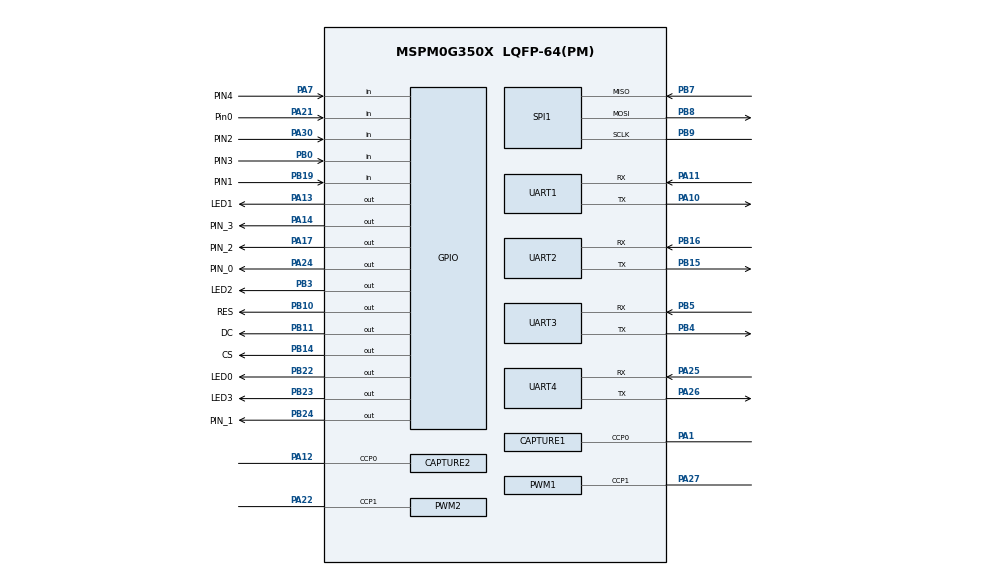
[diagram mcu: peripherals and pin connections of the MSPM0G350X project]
/**
 * @cliArgs --device "MSPM0G350X" --part "Default" --package "LQFP-64(PM)" --product "mspm0_sdk@2.10.00.04"
 * @versions {"tool":"1.26.2+4477"}
 */

/**
 * Import the modules used in this configuration.
 */
const ADC12         = scripting.addModule("/ti/driverlib/ADC12", {}, false);
const ADC121        = ADC12.addInstance();
const CAPTURE       = scripting.addModule("/ti/driverlib/CAPTURE", {}, false);
const CAPTURE1      = CAPTURE.addInstance();
const CAPTURE2      = CAPTURE.addInstance();
const GPIO          = scripting.addModule("/ti/driverlib/GPIO", {}, false);
const GPIO1         = GPIO.addInstance();
const GPIO2         = GPIO.addInstance();
const GPIO3         = GPIO.addInstance();
const GPIO4         = GPIO.addInstance();
const GPIO5         = GPIO.addInstance();
const GPIO6         = GPIO.addInstance();
const GPIO7         = GPIO.addInstance();
const GPIO8         = GPIO.addInstance();
const GPIO9         = GPIO.addInstance();
const MATHACL       = scripting.addModule("/ti/driverlib/MATHACL");
const PWM           = scripting.addModule("/ti/driverlib/PWM", {}, false);
const PWM1          = PWM.addInstance();
const PWM2          = PWM.addInstance();
const PWM3          = PWM.addInstance();
const SPI           = scripting.addModule("/ti/driverlib/SPI", {}, false);
const SPI1          = SPI.addInstance();
const SYSCTL        = scripting.addModule("/ti/driverlib/SYSCTL");
const SYSTICK       = scripting.addModule("/ti/driverlib/SYSTICK");
const TIMER         = scripting.addModule("/ti/driverlib/TIMER", {}, false);
const TIMER1        = TIMER.addInstance();
const UART          = scripting.addModule("/ti/driverlib/UART", {}, false);
const UART1         = UART.addInstance();
const UART2         = UART.addInstance();
const UART3         = UART.addInstance();
const UART4         = UART.addInstance();
const ProjectConfig = scripting.addModule("/ti/project_config/ProjectConfig");

/**
 * Write custom configuration values to the imported modules.
 */
const divider6       = system.clockTree["PLL_CLK2X_DIV"];
divider6.divideValue = 4;

const divider9       = system.clockTree["UDIV"];
divider9.divideValue = 2;

const multiplier2         = system.clockTree["PLL_QDIV"];
multiplier2.multiplyValue = 4;

const mux4       = system.clockTree["EXHFMUX"];
mux4.inputSelect = "EXHFMUX_XTAL";

const mux8       = system.clockTree["HSCLKMUX"];
mux8.inputSelect = "HSCLKMUX_SYSPLL0";

const mux12       = system.clockTree["SYSPLLMUX"];
mux12.inputSelect = "zSYSPLLMUX_HFCLK";

const pinFunction4        = system.clockTree["HFXT"];
pinFunction4.inputFreq    = 40;
pinFunction4.enable       = true;
pinFunction4.HFXTStartup  = 10;
pinFunction4.HFCLKMonitor = true;

ADC121.$name                      = "ADC12_0";
ADC121.peripheral.$assign         = "ADC1";
ADC121.peripheral.adcPin0.$assign = "PA15";
ADC121.adcPin0Config.$name        = "ti_driverlib_gpio_GPIOPinGeneric12";

const Board = scripting.addModule("/ti/driverlib/Board", {}, false);

CAPTURE1.captMode                           = "COMBINED";
CAPTURE1.interrupts                         = ["CC1_DN","ZERO"];
CAPTURE1.timerClkPrescale                   = 2;
CAPTURE1.timerPeriod                        = "3.2768ms";
CAPTURE1.$name                              = "CAPTURE_Up";
CAPTURE1.captFilter                         = true;
CAPTURE1.filterPeriod                       = "PER_8";
CAPTURE1.peripheral.$assign                 = "TIMG8";
CAPTURE1.peripheral.ccp0Pin.$assign         = "PA1";
CAPTURE1.ccp0PinConfig.hideOutputInversion  = scripting.forceWrite(false);
CAPTURE1.ccp0PinConfig.onlyInternalResistor = scripting.forceWrite(false);
CAPTURE1.ccp0PinConfig.passedPeripheralType = scripting.forceWrite("Digital");
CAPTURE1.ccp0PinConfig.$name                = "ti_driverlib_gpio_GPIOPinGeneric4";

CAPTURE2.captMode                           = "COMBINED";
CAPTURE2.interrupts                         = ["CC1_DN","ZERO"];
CAPTURE2.timerPeriod                        = "3.2768ms";
CAPTURE2.timerClkPrescale                   = 2;
CAPTURE2.$name                              = "CAPTURE_Down";
CAPTURE2.captFilter                         = true;
CAPTURE2.filterPeriod                       = "PER_8";
CAPTURE2.peripheral.$assign                 = "TIMG0";
CAPTURE2.peripheral.ccp0Pin.$assign         = "PA12";
CAPTURE2.ccp0PinConfig.hideOutputInversion  = scripting.forceWrite(false);
CAPTURE2.ccp0PinConfig.onlyInternalResistor = scripting.forceWrite(false);
CAPTURE2.ccp0PinConfig.passedPeripheralType = scripting.forceWrite("Digital");
CAPTURE2.ccp0PinConfig.$name                = "ti_driverlib_gpio_GPIOPinGeneric5";

GPIO1.$name                         = "DIR_UP";
GPIO1.associatedPins[0].$name       = "PIN_0";
GPIO1.associatedPins[0].pin.$assign = "PA24";

GPIO2.$name                         = "EN_UP";
GPIO2.associatedPins[0].$name       = "PIN_1";
GPIO2.associatedPins[0].pin.$assign = "PB24";

GPIO3.$name                         = "EN_DOWN";
GPIO3.associatedPins[0].$name       = "PIN_2";
GPIO3.associatedPins[0].pin.$assign = "PA17";

GPIO4.$name                         = "DIR_DOWN";
GPIO4.associatedPins[0].$name       = "PIN_3";
GPIO4.associatedPins[0].pin.$assign = "PA14";

GPIO5.$name                          = "LED";
GPIO5.associatedPins.create(4);
GPIO5.associatedPins[0].$name        = "LED0";
GPIO5.associatedPins[0].pin.$assign  = "PB22";
GPIO5.associatedPins[1].$name        = "LED1";
GPIO5.associatedPins[1].initialValue = "SET";
GPIO5.associatedPins[1].pin.$assign  = "PA13";
GPIO5.associatedPins[2].$name        = "LED2";
GPIO5.associatedPins[2].initialValue = "SET";
GPIO5.associatedPins[2].pin.$assign  = "PB3";
GPIO5.associatedPins[3].$name        = "LED3";
GPIO5.associatedPins[3].initialValue = "SET";
GPIO5.associatedPins[3].pin.$assign  = "PB23";

GPIO6.$name                              = "BUTTON";
GPIO6.associatedPins.create(5);
GPIO6.associatedPins[0].$name            = "Pin0";
GPIO6.associatedPins[0].direction        = "INPUT";
GPIO6.associatedPins[0].internalResistor = "PULL_UP";
GPIO6.associatedPins[0].pin.$assign      = "PA21";
GPIO6.associatedPins[1].$name            = "PIN1";
GPIO6.associatedPins[1].direction        = "INPUT";
GPIO6.associatedPins[1].internalResistor = "PULL_UP";
GPIO6.associatedPins[1].pin.$assign      = "PB19";
GPIO6.associatedPins[2].$name            = "PIN2";
GPIO6.associatedPins[2].direction        = "INPUT";
GPIO6.associatedPins[2].internalResistor = "PULL_UP";
GPIO6.associatedPins[2].pin.$assign      = "PA30";
GPIO6.associatedPins[3].$name            = "PIN3";
GPIO6.associatedPins[3].direction        = "INPUT";
GPIO6.associatedPins[3].internalResistor = "PULL_UP";
GPIO6.associatedPins[3].pin.$assign      = "PB0";
GPIO6.associatedPins[4].$name            = "PIN4";
GPIO6.associatedPins[4].direction        = "INPUT";
GPIO6.associatedPins[4].internalResistor = "PULL_UP";
GPIO6.associatedPins[4].pin.$assign      = "PA7";

GPIO7.$name                          = "OLED";
GPIO7.associatedPins.create(3);
GPIO7.associatedPins[0].ioStructure  = "SD";
GPIO7.associatedPins[0].$name        = "CS";
GPIO7.associatedPins[0].initialValue = "SET";
GPIO7.associatedPins[0].pin.$assign  = "PB14";
GPIO7.associatedPins[1].ioStructure  = "SD";
GPIO7.associatedPins[1].$name        = "RES";
GPIO7.associatedPins[1].pin.$assign  = "PB10";
GPIO7.associatedPins[2].ioStructure  = "SD";
GPIO7.associatedPins[2].$name        = "DC";
GPIO7.associatedPins[2].pin.$assign  = "PB11";

GPIO8.$name                   = "GPIO_GRP_0";
GPIO8.associatedPins[0].$name = "PIN_4";

GPIO9.$name                          = "FLASH";
GPIO9.associatedPins[0].$name        = "CS_FLASH";
GPIO9.associatedPins[0].initialValue = "SET";

PWM1.ccIndex                            = [1];
PWM1.enableShadowLoad                   = true;
PWM1.clockDivider                       = 8;
PWM1.clockPrescale                      = 200;
PWM1.$name                              = "PWM_Up";
PWM1.ccp1PinConfig.direction            = scripting.forceWrite("OUTPUT");
PWM1.ccp1PinConfig.hideOutputInversion  = scripting.forceWrite(false);
PWM1.ccp1PinConfig.onlyInternalResistor = scripting.forceWrite(false);
PWM1.ccp1PinConfig.passedPeripheralType = scripting.forceWrite("Digital");
PWM1.ccp1PinConfig.$name                = "ti_driverlib_gpio_GPIOPinGeneric2";
PWM1.peripheral.$assign                 = "TIMG7";
PWM1.peripheral.ccp1Pin.$assign         = "PA27";
PWM1.PWM_CHANNEL_1.$name                = "ti_driverlib_pwm_PWMTimerCC0";
PWM1.PWM_CHANNEL_1.dutyCycle            = 50;

PWM2.ccIndex                            = [1];
PWM2.enableShadowLoad                   = true;
PWM2.clockDivider                       = 8;
PWM2.clockPrescale                      = 200;
PWM2.$name                              = "PWM_Under";
PWM2.ccp1PinConfig.direction            = scripting.forceWrite("OUTPUT");
PWM2.ccp1PinConfig.hideOutputInversion  = scripting.forceWrite(false);
PWM2.ccp1PinConfig.onlyInternalResistor = scripting.forceWrite(false);
PWM2.ccp1PinConfig.passedPeripheralType = scripting.forceWrite("Digital");
PWM2.ccp1PinConfig.$name                = "ti_driverlib_gpio_GPIOPinGeneric3";
PWM2.peripheral.$assign                 = "TIMG6";
PWM2.peripheral.ccp1Pin.$assign         = "PA22";
PWM2.PWM_CHANNEL_1.$name                = "ti_driverlib_pwm_PWMTimerCC1";
PWM2.PWM_CHANNEL_1.dutyCycle            = 50;

PWM3.$name                              = "Buzzer";
PWM3.ccIndex                            = [0];
PWM3.timerCount                         = 300000;
PWM3.PWM_CHANNEL_0.$name                = "ti_driverlib_pwm_PWMTimerCC2";
PWM3.PWM_CHANNEL_0.dutyCycle            = 50;
PWM3.ccp0PinConfig.direction            = scripting.forceWrite("OUTPUT");
PWM3.ccp0PinConfig.hideOutputInversion  = scripting.forceWrite(false);
PWM3.ccp0PinConfig.onlyInternalResistor = scripting.forceWrite(false);
PWM3.ccp0PinConfig.passedPeripheralType = scripting.forceWrite("Digital");
PWM3.ccp0PinConfig.$name                = "ti_driverlib_gpio_GPIOPinGeneric16";
PWM3.peripheral.$assign                 = "TIMG12";

SPI1.frameFormat                        = "MOTO3";
SPI1.$name                              = "SPI1";
SPI1.targetBitRate                      = 20000000;
SPI1.sclkPinConfig.direction            = scripting.forceWrite("OUTPUT");
SPI1.sclkPinConfig.onlyInternalResistor = scripting.forceWrite(false);
SPI1.sclkPinConfig.passedPeripheralType = scripting.forceWrite("Digital");
SPI1.sclkPinConfig.$name                = "ti_driverlib_gpio_GPIOPinGeneric13";
SPI1.mosiPinConfig.direction            = scripting.forceWrite("OUTPUT");
SPI1.mosiPinConfig.hideOutputInversion  = scripting.forceWrite(false);
SPI1.mosiPinConfig.onlyInternalResistor = scripting.forceWrite(false);
SPI1.mosiPinConfig.passedPeripheralType = scripting.forceWrite("Digital");
SPI1.mosiPinConfig.$name                = "ti_driverlib_gpio_GPIOPinGeneric14";
SPI1.misoPinConfig.onlyInternalResistor = scripting.forceWrite(false);
SPI1.misoPinConfig.passedPeripheralType = scripting.forceWrite("Digital");
SPI1.misoPinConfig.$name                = "ti_driverlib_gpio_GPIOPinGeneric15";
SPI1.peripheral.sclkPin.$assign         = "PB9";
SPI1.peripheral.mosiPin.$assign         = "PB8";
SPI1.peripheral.misoPin.$assign         = "PB7";

SYSCTL.forceDefaultClkConfig = true;
SYSCTL.clockTreeEn           = true;

SYSTICK.period            = 80000;
SYSTICK.interruptEnable   = true;
SYSTICK.interruptPriority = "0";
SYSTICK.periodEnable      = true;
SYSTICK.systickEnable     = true;

TIMER1.timerMode          = "PERIODIC";
TIMER1.interrupts         = ["ZERO"];
TIMER1.$name              = "Timer_Gimbal";
TIMER1.timerClkPrescale   = 5;
TIMER1.timerPeriod        = "2ms";
TIMER1.peripheral.$assign = "TIMA0";

UART1.$name                    = "UART_0";
UART1.enabledInterrupts        = ["RX"];
UART1.targetBaudRate           = 115200;
UART1.digitalGlitchFilter      = 5;
UART1.interruptPriority        = "1";
UART1.peripheral.rxPin.$assign = "PA11";
UART1.peripheral.txPin.$assign = "PA10";
UART1.txPinConfig.$name        = "ti_driverlib_gpio_GPIOPinGeneric0";
UART1.rxPinConfig.$name        = "ti_driverlib_gpio_GPIOPinGeneric1";

UART2.enabledInterrupts                = ["RX"];
UART2.targetBaudRate                   = 115200;
UART2.digitalGlitchFilter              = 5;
UART2.interruptPriority                = "1";
UART2.$name                            = "UART_K230";
UART2.peripheral.$assign               = "UART2";
UART2.peripheral.rxPin.$assign         = "PB16";
UART2.peripheral.txPin.$assign         = "PB15";
UART2.txPinConfig.direction            = scripting.forceWrite("OUTPUT");
UART2.txPinConfig.hideOutputInversion  = scripting.forceWrite(false);
UART2.txPinConfig.onlyInternalResistor = scripting.forceWrite(false);
UART2.txPinConfig.passedPeripheralType = scripting.forceWrite("Digital");
UART2.txPinConfig.$name                = "ti_driverlib_gpio_GPIOPinGeneric6";
UART2.rxPinConfig.hideOutputInversion  = scripting.forceWrite(false);
UART2.rxPinConfig.onlyInternalResistor = scripting.forceWrite(false);
UART2.rxPinConfig.passedPeripheralType = scripting.forceWrite("Digital");
UART2.rxPinConfig.$name                = "ti_driverlib_gpio_GPIOPinGeneric7";

UART3.$name                            = "UART_1";
UART3.peripheral.rxPin.$assign         = "PB5";
UART3.peripheral.txPin.$assign         = "PB4";
UART3.txPinConfig.direction            = scripting.forceWrite("OUTPUT");
UART3.txPinConfig.hideOutputInversion  = scripting.forceWrite(false);
UART3.txPinConfig.onlyInternalResistor = scripting.forceWrite(false);
UART3.txPinConfig.passedPeripheralType = scripting.forceWrite("Digital");
UART3.txPinConfig.$name                = "ti_driverlib_gpio_GPIOPinGeneric8";
UART3.rxPinConfig.hideOutputInversion  = scripting.forceWrite(false);
UART3.rxPinConfig.onlyInternalResistor = scripting.forceWrite(false);
UART3.rxPinConfig.passedPeripheralType = scripting.forceWrite("Digital");
UART3.rxPinConfig.$name                = "ti_driverlib_gpio_GPIOPinGeneric9";

UART4.$name                    = "UART_3";
UART4.peripheral.rxPin.$assign = "PA25";
UART4.peripheral.txPin.$assign = "PA26";
UART4.txPinConfig.$name        = "ti_driverlib_gpio_GPIOPinGeneric10";
UART4.rxPinConfig.$name        = "ti_driverlib_gpio_GPIOPinGeneric11";

ProjectConfig.genLibIQ        = true;
ProjectConfig.genLibIQVersion = "MATHACL";

/**
 * Pinmux solution for unlocked pins/peripherals. This ensures that minor changes to the automatic solver in a future
 * version of the tool will not impact the pinmux you originally saw.  These lines can be completely deleted in order to
 * re-solve from scratch.
 */
pinFunction4.peripheral.$suggestSolution           = "SYSCTL";
pinFunction4.peripheral.hfxInPin.$suggestSolution  = "PA5";
pinFunction4.peripheral.hfxOutPin.$suggestSolution = "PA6";
Board.peripheral.$suggestSolution                  = "DEBUGSS";
Board.peripheral.swclkPin.$suggestSolution         = "PA20";
Board.peripheral.swdioPin.$suggestSolution         = "PA19";
GPIO8.associatedPins[0].pin.$suggestSolution       = "PA16";
GPIO9.associatedPins[0].pin.$suggestSolution       = "PA18";
PWM3.peripheral.ccp0Pin.$suggestSolution           = "PB13";
SPI1.peripheral.$suggestSolution                   = "SPI1";
UART1.peripheral.$suggestSolution                  = "UART0";
UART3.peripheral.$suggestSolution                  = "UART1";
UART4.peripheral.$suggestSolution                  = "UART3";
